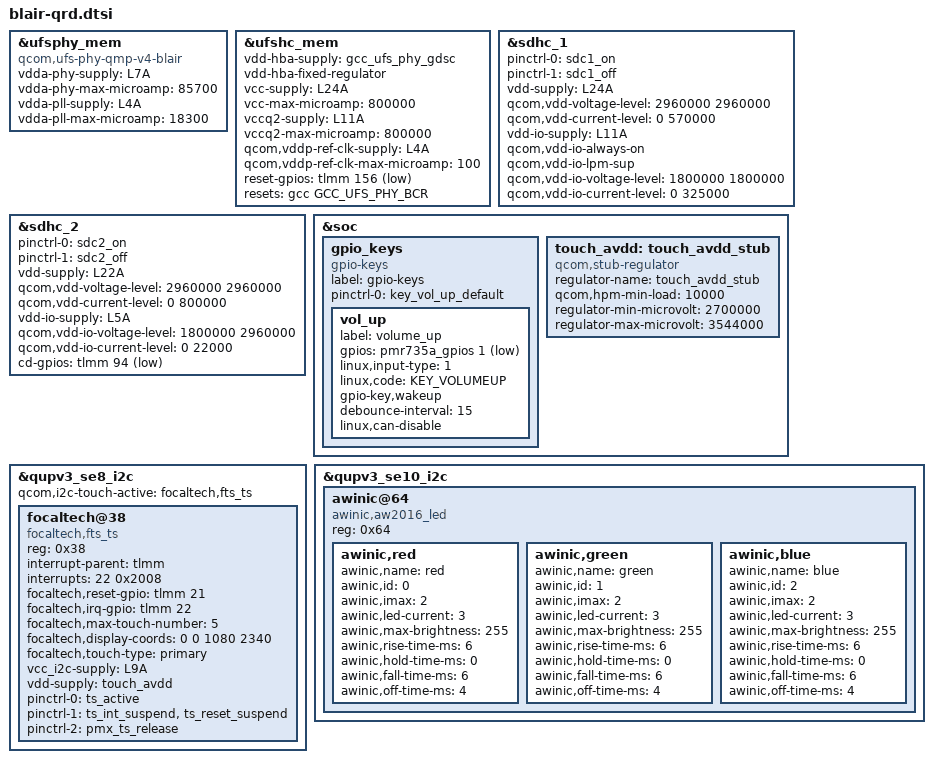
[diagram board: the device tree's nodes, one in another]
#include <dt-bindings/gpio/gpio.h>
#include <dt-bindings/input/linux-event-codes.h>
#include "blair-pmic-overlay-pm6125.dtsi"
#include <dt-bindings/clock/qcom,gcc-blair.h>

&ufsphy_mem {
	compatible = "qcom,ufs-phy-qmp-v4-blair";

	/* VDDA_UFS_CORE */
	vdda-phy-supply = <&L7A>;
	vdda-phy-max-microamp = <85700>;

	/* VDDA_UFS_0_1P2 */
	vdda-pll-supply = <&L4A>;
	vdda-pll-max-microamp = <18300>;

	status = "ok";
};

&ufshc_mem {
	vdd-hba-supply = <&gcc_ufs_phy_gdsc>;
	vdd-hba-fixed-regulator;

	vcc-supply = <&L24A>;
	vcc-max-microamp = <800000>;

	vccq2-supply = <&L11A>;
	vccq2-max-microamp = <800000>;

	/* VDD_PX10 is voted for the ufs_reset_n */
	qcom,vddp-ref-clk-supply = <&L4A>;
	qcom,vddp-ref-clk-max-microamp = <100>;

	reset-gpios = <&tlmm 156 GPIO_ACTIVE_LOW>;
	resets = <&gcc GCC_UFS_PHY_BCR>;
	reset-names = "rst";

	status = "ok";
};

&sdhc_1 {
	status = "ok";

	pinctrl-names = "default", "sleep";
	pinctrl-0 = <&sdc1_on>;
	pinctrl-1 = <&sdc1_off>;

	vdd-supply = <&L24A>;
	qcom,vdd-voltage-level = <2960000 2960000>;
	qcom,vdd-current-level = <0 570000>;

	vdd-io-supply = <&L11A>;
	qcom,vdd-io-always-on;
	qcom,vdd-io-lpm-sup;
	qcom,vdd-io-voltage-level = <1800000 1800000>;
	qcom,vdd-io-current-level = <0 325000>;
};

&sdhc_2 {
	status = "ok";

	pinctrl-names = "default", "sleep";
	pinctrl-0 = <&sdc2_on>;
	pinctrl-1 = <&sdc2_off>;

	vdd-supply = <&L22A>;
	qcom,vdd-voltage-level = <2960000 2960000>;
	qcom,vdd-current-level = <0 800000>;

	vdd-io-supply = <&L5A>;
	qcom,vdd-io-voltage-level = <1800000 2960000>;
	qcom,vdd-io-current-level = <0 22000>;

	cd-gpios = <&tlmm 94 GPIO_ACTIVE_LOW>;
};

&soc {
	gpio_keys {
		compatible = "gpio-keys";
		label = "gpio-keys";

		pinctrl-names = "default";
		pinctrl-0 = <&key_vol_up_default>;

		vol_up {
			label = "volume_up";
			gpios = <&pmr735a_gpios 1 GPIO_ACTIVE_LOW>;
			linux,input-type = <1>;
			linux,code = <KEY_VOLUMEUP>;
			gpio-key,wakeup;
			debounce-interval = <15>;
			linux,can-disable;
		};
	};

	touch_avdd: touch_avdd_stub {
		/*
		 * Touch eLDO controlled by gpio#53 is always ON.
		 * Using dummy regulator.
		 */
		compatible = "qcom,stub-regulator";
		regulator-name = "touch_avdd_stub";
		qcom,hpm-min-load = <10000>;
		regulator-min-microvolt = <2700000>;
		regulator-max-microvolt = <3544000>;
	};
};

&qupv3_se8_i2c {
	#address-cells = <1>;
	#size-cells = <0>;
	status = "okay";
	qcom,i2c-touch-active= "focaltech,fts_ts";

	focaltech@38 {
		compatible = "focaltech,fts_ts";
		reg = <0x38>;
		interrupt-parent = <&tlmm>;
		interrupts = <22 0x2008>;
		focaltech,reset-gpio = <&tlmm 21 0x00>;
		focaltech,irq-gpio = <&tlmm 22 0x2008>;
		focaltech,max-touch-number = <5>;
		focaltech,display-coords = <0 0 1080 2340>;
		focaltech,touch-type = "primary";

		vcc_i2c-supply = <&L9A>;
		vdd-supply = <&touch_avdd>;

		pinctrl-names = "pmx_ts_active", "pmx_ts_suspend",
				"pmx_ts_release";
		pinctrl-0 = <&ts_active>;
		pinctrl-1 = <&ts_int_suspend &ts_reset_suspend>;
		pinctrl-2 = <&pmx_ts_release>;
	};
};

&qupv3_se10_i2c {
	awinic@64 {
		compatible = "awinic,aw2016_led";
		reg = <0x64>;

		awinic,red {
			awinic,name = "red";
			awinic,id = <0>;
			awinic,imax = <2>;
			awinic,led-current = <3>;
			awinic,max-brightness = <255>;
			awinic,rise-time-ms = <6>;
			awinic,hold-time-ms = <0>;
			awinic,fall-time-ms = <6>;
			awinic,off-time-ms = <4>;
		};

		awinic,green {
			awinic,name = "green";
			awinic,id = <1>;
			awinic,imax = <2>;
			awinic,led-current = <3>;
			awinic,max-brightness = <255>;
			awinic,rise-time-ms = <6>;
			awinic,hold-time-ms = <0>;
			awinic,fall-time-ms = <6>;
			awinic,off-time-ms = <4>;
		};

		awinic,blue {
			awinic,name = "blue";
			awinic,id = <2>;
			awinic,imax = <2>;
			awinic,led-current = <3>;
			awinic,max-brightness = <255>;
			awinic,rise-time-ms = <6>;
			awinic,hold-time-ms = <0>;
			awinic,fall-time-ms = <6>;
			awinic,off-time-ms = <4>;
		};
	};
};
